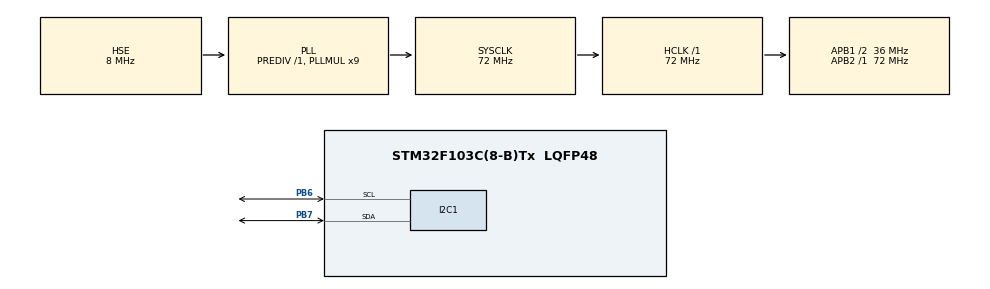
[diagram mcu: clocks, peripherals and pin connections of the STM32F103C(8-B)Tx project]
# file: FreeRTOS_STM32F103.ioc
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FREERTOS.BinarySemaphores01=myBinarySem01,Dynamic,NULL
FREERTOS.Tasks01=defaultTask,0,128,StartDefaultTask,Default,NULL,Dynamic,NULL,NULL;myTask02,-3,128,StartTask02,Default,NULL,Dynamic,NULL,NULL
I2C1.I2C_Mode=I2C_Fast
Mcu.Family=STM32F1
Mcu.Name=STM32F103C(8-B)Tx
Mcu.Package=LQFP48
NVIC.PriorityGroup=NVIC_PRIORITYGROUP_4
NVIC.TIM1_UP_IRQn=true\:0\:0\:false\:false\:true\:false\:false
NVIC.TimeBase=TIM1_UP_IRQn
NVIC.TimeBaseIP=TIM1
PA13.Mode=Serial_Wire
PA13.Signal=SYS_JTMS-SWDIO
PA14.Mode=Serial_Wire
PA14.Signal=SYS_JTCK-SWCLK
PB6.Mode=I2C
PB6.Signal=I2C1_SCL
PB7.Mode=I2C
PB7.Signal=I2C1_SDA
PD0-OSC_IN.Mode=HSE-External-Oscillator
PD0-OSC_IN.Signal=RCC_OSC_IN
PD1-OSC_OUT.Mode=HSE-External-Oscillator
PD1-OSC_OUT.Signal=RCC_OSC_OUT
ProjectManager.HeapSize=0x200
ProjectManager.StackSize=0x400
ProjectManager.TargetToolchain=EWARM
RCC.AHBFreq_Value=72000000
RCC.APB1CLKDivider=RCC_HCLK_DIV2
RCC.APB1Freq_Value=36000000
RCC.APB1TimFreq_Value=72000000
RCC.APB2Freq_Value=72000000
RCC.APB2TimFreq_Value=72000000
RCC.HCLKFreq_Value=72000000
RCC.PLLMUL=RCC_PLL_MUL9
RCC.PLLSourceVirtual=RCC_PLLSOURCE_HSE
RCC.SYSCLKFreq_VALUE=72000000
RCC.SYSCLKSource=RCC_SYSCLKSOURCE_PLLCLK
RCC.USBFreq_Value=72000000
VP_FREERTOS_VS_ENABLE.Mode=Enabled
VP_SYS_VS_tim1.Mode=TIM1
board=FreeRTOS_STM32F103

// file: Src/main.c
/**
  ******************************************************************************
  * File Name          : main.c
  * Description        : Main program body
  ******************************************************************************
  * This notice applies to any and all portions of this file
  * that are not between comment pairs USER CODE BEGIN and
  * USER CODE END. Other portions of this file, whether
  * inserted by the user or by software development tools
  * are owned by their respective copyright owners.
  *
  * Copyright (c) 2019 STMicroelectronics International N.V.
  * All rights reserved.
  *
  * Redistribution and use in source and binary forms, with or without
  * modification, are permitted, provided that the following conditions are met:
  *
  * 1. Redistribution of source code must retain the above copyright notice,
  *    this list of conditions and the following disclaimer.
  * 2. Redistributions in binary form must reproduce the above copyright notice,
  *    this list of conditions and the following disclaimer in the documentation
  *    and/or other materials provided with the distribution.
  * 3. Neither the name of STMicroelectronics nor the names of other
  *    contributors to this software may be used to endorse or promote products
  *    derived from this software without specific written permission.
  * 4. This software, including modifications and/or derivative works of this
  *    software, must execute solely and exclusively on microcontroller or
  *    microprocessor devices manufactured by or for STMicroelectronics.
  * 5. Redistribution and use of this software other than as permitted under
  *    this license is void and will automatically terminate your rights under
  *    this license.
  *
  * THIS SOFTWARE IS PROVIDED BY STMICROELECTRONICS AND CONTRIBUTORS "AS IS"
  * AND ANY EXPRESS, IMPLIED OR STATUTORY WARRANTIES, INCLUDING, BUT NOT
  * LIMITED TO, THE IMPLIED WARRANTIES OF MERCHANTABILITY, FITNESS FOR A
  * PARTICULAR PURPOSE AND NON-INFRINGEMENT OF THIRD PARTY INTELLECTUAL PROPERTY
  * RIGHTS ARE DISCLAIMED TO THE FULLEST EXTENT PERMITTED BY LAW. IN NO EVENT
  * SHALL STMICROELECTRONICS OR CONTRIBUTORS BE LIABLE FOR ANY DIRECT, INDIRECT,
  * INCIDENTAL, SPECIAL, EXEMPLARY, OR CONSEQUENTIAL DAMAGES (INCLUDING, BUT NOT
  * LIMITED TO, PROCUREMENT OF SUBSTITUTE GOODS OR SERVICES; LOSS OF USE, DATA,
  * OR PROFITS; OR BUSINESS INTERRUPTION) HOWEVER CAUSED AND ON ANY THEORY OF
  * LIABILITY, WHETHER IN CONTRACT, STRICT LIABILITY, OR TORT (INCLUDING
  * NEGLIGENCE OR OTHERWISE) ARISING IN ANY WAY OUT OF THE USE OF THIS SOFTWARE,
  * EVEN IF ADVISED OF THE POSSIBILITY OF SUCH DAMAGE.
  *
  ******************************************************************************
  */
#include "main.h"
#include "stm32f1xx_hal.h"
#include "cmsis_os.h"

/* USER CODE BEGIN Includes */
#include "SSD1602.h"
/* USER CODE END Includes */

I2C_HandleTypeDef hi2c1;

osThreadId defaultTaskHandle;
osThreadId myTask02Handle;
osSemaphoreId myBinarySem01Handle;

/* USER CODE BEGIN PV */
/* Private variables ---------------------------------------------------------*/
volatile uint32_t TIM1_Count=0, TIM1_Count_Sec=0;
char str1[20];
volatile uint8_t tasks_started=0;
uint32_t ncount1=0, ncount2=0;
/* USER CODE END PV */

void SystemClock_Config(void);
static void MX_GPIO_Init(void);
static void MX_I2C1_Init(void);
void StartDefaultTask(void const * argument);
void StartTask02(void const * argument);

/* USER CODE BEGIN PFP */
/* Private function prototypes -----------------------------------------------*/

/* USER CODE END PFP */

int main(void)
{

  /* MCU Configuration----------------------------------------------------------*/

  /* Reset of all peripherals, Initializes the Flash interface and the Systick. */
  HAL_Init();

  /* Configure the system clock */
  SystemClock_Config();

  /* Initialize all configured peripherals */
  MX_GPIO_Init();
  MX_I2C1_Init();

  /* USER CODE BEGIN 2 */
  HAL_Delay(100);
  OLED_init(&hi2c1);
  LCD_Clear(&hi2c1);
  LCD_Goto(&hi2c1, 0,0);
  OLED_string(&hi2c1, " Tasks");
  LCD_Goto(&hi2c1, 42,0);
  OLED_string(&hi2c1, " Work");
  LCD_Goto(&hi2c1, 70,0);
  OLED_string(&hi2c1, " Wait");
  LCD_Goto(&hi2c1, 0,6);
  OLED_string(&hi2c1, " Common Time");
  LCD_Goto(&hi2c1, 0,2);
  OLED_string(&hi2c1, " TASK_1");
  LCD_Goto(&hi2c1, 0,4);
  OLED_string(&hi2c1, " TASK_2");
  /* USER CODE END 2 */

  /* Create the semaphores(s) */
  /* definition and creation of myBinarySem01 */
  osSemaphoreDef(myBinarySem01);
  myBinarySem01Handle = osSemaphoreCreate(osSemaphore(myBinarySem01), 1);

  /* Create the thread(s) */
  /* definition and creation of defaultTask */
  osThreadDef(defaultTask, StartDefaultTask, osPriorityNormal, 0, 128);
  defaultTaskHandle = osThreadCreate(osThread(defaultTask), NULL);

  /* definition and creation of myTask02 */
  osThreadDef(myTask02, StartTask02, osPriorityIdle, 0, 128);
  myTask02Handle = osThreadCreate(osThread(myTask02), NULL);

  /* Start scheduler */
  osKernelStart();

  /* We should never get here as control is now taken by the scheduler */

  /* Infinite loop */
  while (1)
  {

  }

}

/** System Clock Configuration
*/
void SystemClock_Config(void)
{

  RCC_OscInitTypeDef RCC_OscInitStruct;
  RCC_ClkInitTypeDef RCC_ClkInitStruct;

    /**Initializes the CPU, AHB and APB busses clocks
    */
  RCC_OscInitStruct.OscillatorType = RCC_OSCILLATORTYPE_HSE;
  RCC_OscInitStruct.HSEState = RCC_HSE_ON;
  RCC_OscInitStruct.HSEPredivValue = RCC_HSE_PREDIV_DIV1;
  RCC_OscInitStruct.HSIState = RCC_HSI_ON;
  RCC_OscInitStruct.PLL.PLLState = RCC_PLL_ON;
  RCC_OscInitStruct.PLL.PLLSource = RCC_PLLSOURCE_HSE;
  RCC_OscInitStruct.PLL.PLLMUL = RCC_PLL_MUL9;
  if (HAL_RCC_OscConfig(&RCC_OscInitStruct) != HAL_OK)
  {
    _Error_Handler(__FILE__, __LINE__);
  }

    /**Initializes the CPU, AHB and APB busses clocks
    */
  RCC_ClkInitStruct.ClockType = RCC_CLOCKTYPE_HCLK|RCC_CLOCKTYPE_SYSCLK
                              |RCC_CLOCKTYPE_PCLK1|RCC_CLOCKTYPE_PCLK2;
  RCC_ClkInitStruct.SYSCLKSource = RCC_SYSCLKSOURCE_PLLCLK;
  RCC_ClkInitStruct.AHBCLKDivider = RCC_SYSCLK_DIV1;
  RCC_ClkInitStruct.APB1CLKDivider = RCC_HCLK_DIV2;
  RCC_ClkInitStruct.APB2CLKDivider = RCC_HCLK_DIV1;

  if (HAL_RCC_ClockConfig(&RCC_ClkInitStruct, FLASH_LATENCY_2) != HAL_OK)
  {
    _Error_Handler(__FILE__, __LINE__);
  }

    /**Configure the Systick interrupt time
    */
  HAL_SYSTICK_Config(HAL_RCC_GetHCLKFreq()/1000);

    /**Configure the Systick
    */
  HAL_SYSTICK_CLKSourceConfig(SYSTICK_CLKSOURCE_HCLK);

  /* SysTick_IRQn interrupt configuration */
  HAL_NVIC_SetPriority(SysTick_IRQn, 15, 0);
}

/* I2C1 init function */
static void MX_I2C1_Init(void)
{

  hi2c1.Instance = I2C1;
  hi2c1.Init.ClockSpeed = 400000;
  hi2c1.Init.DutyCycle = I2C_DUTYCYCLE_2;
  hi2c1.Init.OwnAddress1 = 0;
  hi2c1.Init.AddressingMode = I2C_ADDRESSINGMODE_7BIT;
  hi2c1.Init.DualAddressMode = I2C_DUALADDRESS_DISABLE;
  hi2c1.Init.OwnAddress2 = 0;
  hi2c1.Init.GeneralCallMode = I2C_GENERALCALL_DISABLE;
  hi2c1.Init.NoStretchMode = I2C_NOSTRETCH_DISABLE;
  if (HAL_I2C_Init(&hi2c1) != HAL_OK)
  {
    _Error_Handler(__FILE__, __LINE__);
  }

}

/** Configure pins as
        * Analog
        * Input
        * Output
        * EVENT_OUT
        * EXTI
*/
static void MX_GPIO_Init(void)
{

  /* GPIO Ports Clock Enable */
  __HAL_RCC_GPIOD_CLK_ENABLE();
  __HAL_RCC_GPIOA_CLK_ENABLE();
  __HAL_RCC_GPIOB_CLK_ENABLE();

}

/* USER CODE BEGIN 4 */
void PrintCounter(uint8_t ID_Task)
{
  uint8_t i=0;
  if (myBinarySem01Handle != NULL)
    {
      if(osSemaphoreWait(myBinarySem01Handle , 100) == osOK)
        {
          i++;
          for(i=1;i<=50;i++)
          {
            if(ID_Task==1)
            {
              sprintf(str1,"%d ",i);
              LCD_Goto(&hi2c1,50,2);
              OLED_string(&hi2c1, str1);
            }
            else if(ID_Task==2)
            {
              sprintf(str1,"%d ",i);
              LCD_Goto(&hi2c1,50,4);
              OLED_string(&hi2c1, str1);
            }
            osDelay(500);
          }
          if(ID_Task==1)
          {
            LCD_Goto(&hi2c1,50,2);
            OLED_string(&hi2c1,"  ");
            ncount1=0;
          }
          else if(ID_Task==2)
          {
            LCD_Goto(&hi2c1,50,4);
            OLED_string(&hi2c1,"  ");
            ncount2=0;
          }
     osSemaphoreRelease(myBinarySem01Handle);
    }
  }
}
/* USER CODE END 4 */

/* StartDefaultTask function */
void StartDefaultTask(void const * argument)
{

  /* USER CODE BEGIN 5 */
  tasks_started++;
  /* Infinite loop */
  for(;;)
  {
    ncount1++;
    sprintf(str1,"%lu ",ncount1);
    LCD_Goto(&hi2c1,75,2);
    OLED_string(&hi2c1,str1);
    PrintCounter(1);
    osDelay(1);
  }
  /* USER CODE END 5 */
}

/* StartTask02 function */
void StartTask02(void const * argument)
{
  /* USER CODE BEGIN StartTask02 */
  tasks_started++;
  /* Infinite loop */
  for(;;)
  {
    ncount2++;
    sprintf(str1,"%lu ",ncount2);
    LCD_Goto(&hi2c1,75,4);
    OLED_string(&hi2c1,str1);
    PrintCounter(2);
    osDelay(1);
  }
  /* USER CODE END StartTask02 */
}

void HAL_TIM_PeriodElapsedCallback(TIM_HandleTypeDef *htim)
{
  if (htim->Instance == TIM1) {
    HAL_IncTick();
  }
/* USER CODE BEGIN Callback 1 */
  if(tasks_started>=2)
  {
    TIM1_Count++;
    if(TIM1_Count%1000==0)
    {
      TIM1_Count_Sec++;
      sprintf(str1,"%lu ",TIM1_Count_Sec);
      LCD_Goto(&hi2c1,80,6);
      OLED_string(&hi2c1, str1);
    }
    if(TIM1_Count>=10000000) TIM1_Count=0;
  }
/* USER CODE END Callback 1 */
}

void _Error_Handler(char * file, int line)
{
  while(1)
  {
  }
}

/************************ (C) COPYRIGHT STMicroelectronics *****END OF FILE****/
